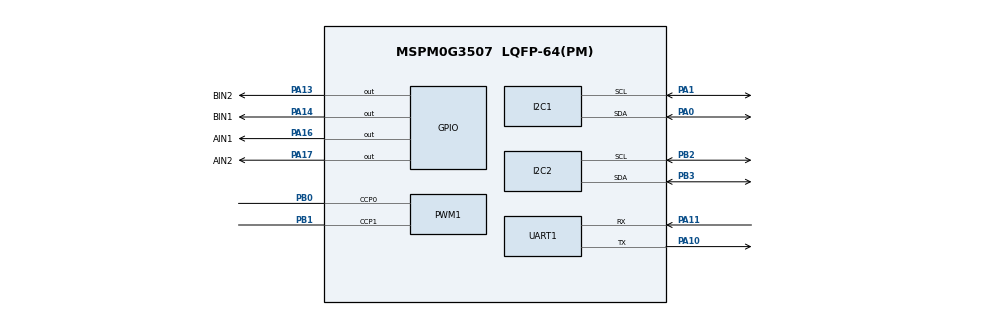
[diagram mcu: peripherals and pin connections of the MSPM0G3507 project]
/**
 * These arguments were used when this file was generated. They will be automatically applied on subsequent loads
 * via the GUI or CLI. Run CLI with '--help' for additional information on how to override these arguments.
 * @cliArgs --device "MSPM0G350X" --part "Default" --package "LQFP-64(PM)" --product "mspm0_sdk@2.10.00.04"
 * @v2CliArgs --device "MSPM0G3507" --package "LQFP-64(PM)" --product "mspm0_sdk@2.10.00.04"
 * @versions {"tool":"1.26.0+4407"}
 */

/**
 * Import the modules used in this configuration.
 */
const GPIO    = scripting.addModule("/ti/driverlib/GPIO", {}, false);
const GPIO1   = GPIO.addInstance();
const I2C     = scripting.addModule("/ti/driverlib/I2C", {}, false);
const I2C1    = I2C.addInstance();
const I2C2    = I2C.addInstance();
const PWM     = scripting.addModule("/ti/driverlib/PWM", {}, false);
const PWM1    = PWM.addInstance();
const SYSCTL  = scripting.addModule("/ti/driverlib/SYSCTL");
const SYSTICK = scripting.addModule("/ti/driverlib/SYSTICK");
const TIMER   = scripting.addModule("/ti/driverlib/TIMER", {}, false);
const TIMER1  = TIMER.addInstance();
const UART    = scripting.addModule("/ti/driverlib/UART", {}, false);
const UART1   = UART.addInstance();

/**
 * Write custom configuration values to the imported modules.
 */
const divider9       = system.clockTree["UDIV"];
divider9.divideValue = 2;

const mux4       = system.clockTree["EXHFMUX"];
mux4.inputSelect = "EXHFMUX_XTAL";

const mux8       = system.clockTree["HSCLKMUX"];
mux8.inputSelect = "HSCLKMUX_SYSPLL2X";

const mux12       = system.clockTree["SYSPLLMUX"];
mux12.inputSelect = "zSYSPLLMUX_HFCLK";

const pinFunction4        = system.clockTree["HFXT"];
pinFunction4.inputFreq    = 40;
pinFunction4.enable       = true;
pinFunction4.HFXTStartup  = 20;
pinFunction4.HFCLKMonitor = true;

GPIO1.$name                          = "TB6612";
GPIO1.port                           = "PORTA";
GPIO1.associatedPins.create(4);
GPIO1.associatedPins[0].$name        = "AIN1";
GPIO1.associatedPins[0].initialValue = "SET";
GPIO1.associatedPins[0].assignedPin  = "16";
GPIO1.associatedPins[0].pin.$assign  = "PA16";
GPIO1.associatedPins[1].$name        = "AIN2";
GPIO1.associatedPins[1].initialValue = "SET";
GPIO1.associatedPins[1].assignedPin  = "17";
GPIO1.associatedPins[1].pin.$assign  = "PA17";
GPIO1.associatedPins[2].$name        = "BIN1";
GPIO1.associatedPins[2].initialValue = "SET";
GPIO1.associatedPins[2].assignedPin  = "14";
GPIO1.associatedPins[2].pin.$assign  = "PA14";
GPIO1.associatedPins[3].$name        = "BIN2";
GPIO1.associatedPins[3].initialValue = "SET";
GPIO1.associatedPins[3].assignedPin  = "13";
GPIO1.associatedPins[3].pin.$assign  = "PA13";

const Board = scripting.addModule("/ti/driverlib/Board", {}, false);

I2C1.$name                             = "I2C_MPU6050";
I2C1.basicEnableController             = true;
I2C1.basicControllerStandardBusSpeed   = "Fast";
I2C1.peripheral.$assign                = "I2C0";
I2C1.peripheral.sdaPin.$assign         = "PA0";
I2C1.peripheral.sclPin.$assign         = "PA1";
I2C1.sdaPinConfig.$name                = "ti_driverlib_gpio_GPIOPinGeneric0";
I2C1.sdaPinConfig.hideOutputInversion  = scripting.forceWrite(false);
I2C1.sdaPinConfig.onlyInternalResistor = scripting.forceWrite(false);
I2C1.sdaPinConfig.passedPeripheralType = scripting.forceWrite("Digital");
I2C1.sclPinConfig.$name                = "ti_driverlib_gpio_GPIOPinGeneric1";
I2C1.sclPinConfig.hideOutputInversion  = scripting.forceWrite(false);
I2C1.sclPinConfig.onlyInternalResistor = scripting.forceWrite(false);
I2C1.sclPinConfig.passedPeripheralType = scripting.forceWrite("Digital");

I2C2.$name                             = "I2C_OLED";
I2C2.basicEnableController             = true;
I2C2.basicControllerStandardBusSpeed   = "Fast";
I2C2.peripheral.$assign                = "I2C1";
I2C2.peripheral.sdaPin.$assign         = "PB3";
I2C2.peripheral.sclPin.$assign         = "PB2";
I2C2.sdaPinConfig.hideOutputInversion  = scripting.forceWrite(false);
I2C2.sdaPinConfig.onlyInternalResistor = scripting.forceWrite(false);
I2C2.sdaPinConfig.passedPeripheralType = scripting.forceWrite("Digital");
I2C2.sdaPinConfig.$name                = "ti_driverlib_gpio_GPIOPinGeneric6";
I2C2.sclPinConfig.hideOutputInversion  = scripting.forceWrite(false);
I2C2.sclPinConfig.onlyInternalResistor = scripting.forceWrite(false);
I2C2.sclPinConfig.passedPeripheralType = scripting.forceWrite("Digital");
I2C2.sclPinConfig.$name                = "ti_driverlib_gpio_GPIOPinGeneric7";

PWM1.$name                      = "PWM_0";
PWM1.clockDivider               = 8;
PWM1.timerStartTimer            = true;
PWM1.peripheral.$assign         = "TIMA1";
PWM1.peripheral.ccp0Pin.$assign = "PB0";
PWM1.peripheral.ccp1Pin.$assign = "PB1";
PWM1.PWM_CHANNEL_0.$name        = "ti_driverlib_pwm_PWMTimerCC0";
PWM1.PWM_CHANNEL_0.invert       = true;
PWM1.PWM_CHANNEL_1.$name        = "ti_driverlib_pwm_PWMTimerCC1";
PWM1.PWM_CHANNEL_1.invert       = true;
PWM1.ccp0PinConfig.$name        = "ti_driverlib_gpio_GPIOPinGeneric2";
PWM1.ccp1PinConfig.$name        = "ti_driverlib_gpio_GPIOPinGeneric3";

SYSCTL.forceDefaultClkConfig = true;
SYSCTL.clockTreeEn           = true;

SYSTICK.periodEnable      = true;
SYSTICK.systickEnable     = true;
SYSTICK.interruptEnable   = true;
SYSTICK.period            = 8000;
SYSTICK.interruptPriority = "2";

TIMER1.$name              = "TIMER_0";
TIMER1.timerClkDiv        = 4;
TIMER1.timerStartTimer    = true;
TIMER1.timerMode          = "PERIODIC";
TIMER1.timerPeriod        = "5 ms";
TIMER1.interrupts         = ["ZERO"];
TIMER1.interruptPriority  = "2";
TIMER1.peripheral.$assign = "TIMG0";

UART1.$name                        = "UART_0";
UART1.targetBaudRate               = 115200;
UART1.peripheral.$assign           = "UART0";
UART1.peripheral.rxPin.$assign     = "PA11";
UART1.peripheral.txPin.$assign     = "PA10";
UART1.txPinConfig.$name            = "ti_driverlib_gpio_GPIOPinGeneric4";
UART1.txPinConfig.enableConfig     = true;
UART1.txPinConfig.internalResistor = "PULL_UP";
UART1.rxPinConfig.$name            = "ti_driverlib_gpio_GPIOPinGeneric5";
UART1.rxPinConfig.enableConfig     = true;

/**
 * Pinmux solution for unlocked pins/peripherals. This ensures that minor changes to the automatic solver in a future
 * version of the tool will not impact the pinmux you originally saw.  These lines can be completely deleted in order to
 * re-solve from scratch.
 */
pinFunction4.peripheral.$suggestSolution           = "SYSCTL";
pinFunction4.peripheral.hfxInPin.$suggestSolution  = "PA5";
pinFunction4.peripheral.hfxOutPin.$suggestSolution = "PA6";
Board.peripheral.$suggestSolution                  = "DEBUGSS";
Board.peripheral.swclkPin.$suggestSolution         = "PA20";
Board.peripheral.swdioPin.$suggestSolution         = "PA19";
